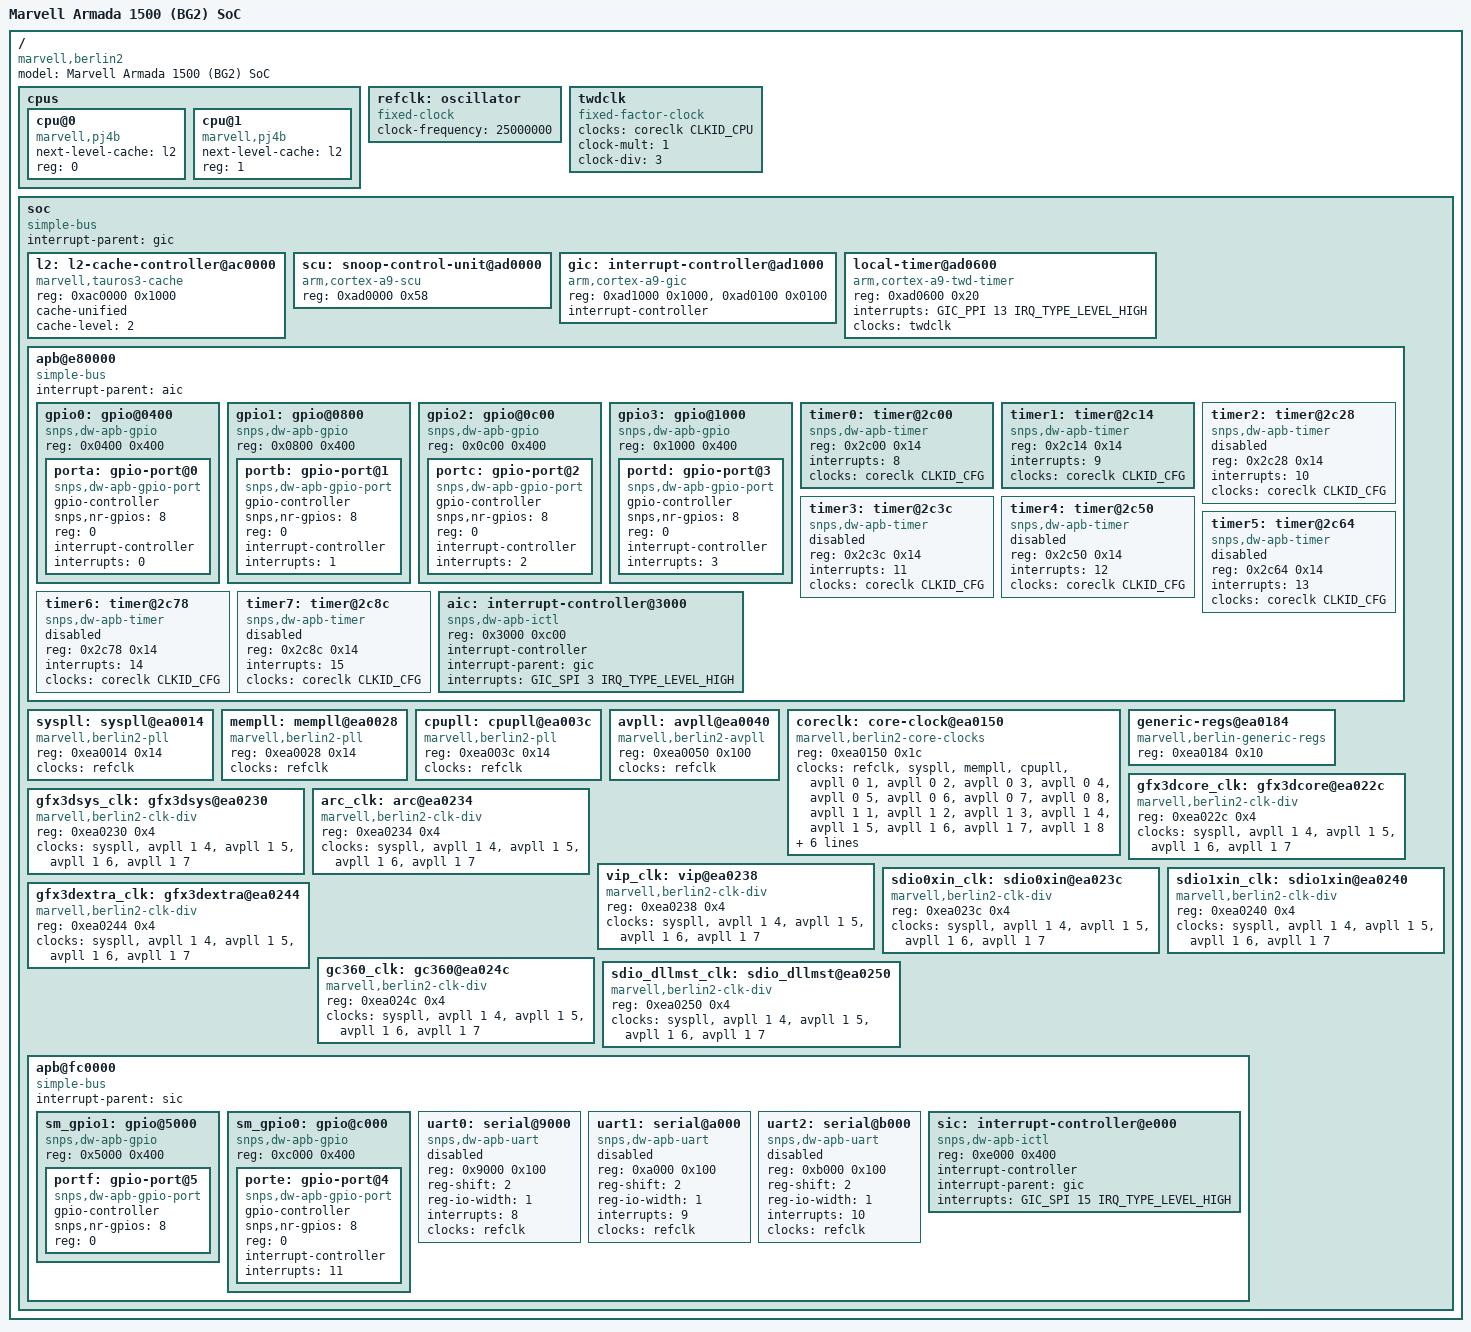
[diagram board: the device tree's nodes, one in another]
/*
 * Device Tree Include file for Marvell Armada 1500 (Berlin BG2) SoC
 *
 * Sebastian Hesselbarth <sebastian.hesselbarth@gmail.com>
 *
 * based on GPL'ed 2.6 kernel sources
 *  (c) Marvell International Ltd.
 *
 * This file is licensed under the terms of the GNU General Public
 * License version 2.  This program is licensed "as is" without any
 * warranty of any kind, whether express or implied.
 */

#include "skeleton.dtsi"
#include <dt-bindings/clock/berlin2.h>
#include <dt-bindings/interrupt-controller/arm-gic.h>

/ {
	model = "Marvell Armada 1500 (BG2) SoC";
	compatible = "marvell,berlin2", "marvell,berlin";

	cpus {
		#address-cells = <1>;
		#size-cells = <0>;

		cpu@0 {
			compatible = "marvell,pj4b";
			device_type = "cpu";
			next-level-cache = <&l2>;
			reg = <0>;
		};

		cpu@1 {
			compatible = "marvell,pj4b";
			device_type = "cpu";
			next-level-cache = <&l2>;
			reg = <1>;
		};
	};

	refclk: oscillator {
		compatible = "fixed-clock";
		#clock-cells = <0>;
		clock-frequency = <25000000>;
	};

	twdclk: twdclk {
		compatible = "fixed-factor-clock";
		#clock-cells = <0>;
		clocks = <&coreclk CLKID_CPU>;
		clock-mult = <1>;
		clock-div = <3>;
	};

	soc {
		compatible = "simple-bus";
		#address-cells = <1>;
		#size-cells = <1>;
		interrupt-parent = <&gic>;

		ranges = <0 0xf7000000 0x1000000>;

		l2: l2-cache-controller@ac0000 {
			compatible = "marvell,tauros3-cache", "arm,pl310-cache";
			reg = <0xac0000 0x1000>;
			cache-unified;
			cache-level = <2>;
		};

		scu: snoop-control-unit@ad0000 {
			compatible = "arm,cortex-a9-scu";
			reg = <0xad0000 0x58>;
		};

		gic: interrupt-controller@ad1000 {
			compatible = "arm,cortex-a9-gic";
			reg = <0xad1000 0x1000>, <0xad0100 0x0100>;
			interrupt-controller;
			#interrupt-cells = <3>;
		};

		local-timer@ad0600 {
			compatible = "arm,cortex-a9-twd-timer";
			reg = <0xad0600 0x20>;
			interrupts = <GIC_PPI 13 IRQ_TYPE_LEVEL_HIGH>;
			clocks = <&twdclk>;
		};

		apb@e80000 {
			compatible = "simple-bus";
			#address-cells = <1>;
			#size-cells = <1>;

			ranges = <0 0xe80000 0x10000>;
			interrupt-parent = <&aic>;

			gpio0: gpio@0400 {
				compatible = "snps,dw-apb-gpio";
				reg = <0x0400 0x400>;
				#address-cells = <1>;
				#size-cells = <0>;

				porta: gpio-port@0 {
					compatible = "snps,dw-apb-gpio-port";
					gpio-controller;
					#gpio-cells = <2>;
					snps,nr-gpios = <8>;
					reg = <0>;
					interrupt-controller;
					#interrupt-cells = <2>;
					interrupts = <0>;
				};
			};

			gpio1: gpio@0800 {
				compatible = "snps,dw-apb-gpio";
				reg = <0x0800 0x400>;
				#address-cells = <1>;
				#size-cells = <0>;

				portb: gpio-port@1 {
					compatible = "snps,dw-apb-gpio-port";
					gpio-controller;
					#gpio-cells = <2>;
					snps,nr-gpios = <8>;
					reg = <0>;
					interrupt-controller;
					#interrupt-cells = <2>;
					interrupts = <1>;
				};
			};

			gpio2: gpio@0c00 {
				compatible = "snps,dw-apb-gpio";
				reg = <0x0c00 0x400>;
				#address-cells = <1>;
				#size-cells = <0>;

				portc: gpio-port@2 {
					compatible = "snps,dw-apb-gpio-port";
					gpio-controller;
					#gpio-cells = <2>;
					snps,nr-gpios = <8>;
					reg = <0>;
					interrupt-controller;
					#interrupt-cells = <2>;
					interrupts = <2>;
				};
			};

			gpio3: gpio@1000 {
				compatible = "snps,dw-apb-gpio";
				reg = <0x1000 0x400>;
				#address-cells = <1>;
				#size-cells = <0>;

				portd: gpio-port@3 {
					compatible = "snps,dw-apb-gpio-port";
					gpio-controller;
					#gpio-cells = <2>;
					snps,nr-gpios = <8>;
					reg = <0>;
					interrupt-controller;
					#interrupt-cells = <2>;
					interrupts = <3>;
				};
			};

			timer0: timer@2c00 {
				compatible = "snps,dw-apb-timer";
				reg = <0x2c00 0x14>;
				interrupts = <8>;
				clocks = <&coreclk CLKID_CFG>;
				clock-names = "timer";
				status = "okay";
			};

			timer1: timer@2c14 {
				compatible = "snps,dw-apb-timer";
				reg = <0x2c14 0x14>;
				interrupts = <9>;
				clocks = <&coreclk CLKID_CFG>;
				clock-names = "timer";
				status = "okay";
			};

			timer2: timer@2c28 {
				compatible = "snps,dw-apb-timer";
				reg = <0x2c28 0x14>;
				interrupts = <10>;
				clocks = <&coreclk CLKID_CFG>;
				clock-names = "timer";
				status = "disabled";
			};

			timer3: timer@2c3c {
				compatible = "snps,dw-apb-timer";
				reg = <0x2c3c 0x14>;
				interrupts = <11>;
				clocks = <&coreclk CLKID_CFG>;
				clock-names = "timer";
				status = "disabled";
			};

			timer4: timer@2c50 {
				compatible = "snps,dw-apb-timer";
				reg = <0x2c50 0x14>;
				interrupts = <12>;
				clocks = <&coreclk CLKID_CFG>;
				clock-names = "timer";
				status = "disabled";
			};

			timer5: timer@2c64 {
				compatible = "snps,dw-apb-timer";
				reg = <0x2c64 0x14>;
				interrupts = <13>;
				clocks = <&coreclk CLKID_CFG>;
				clock-names = "timer";
				status = "disabled";
			};

			timer6: timer@2c78 {
				compatible = "snps,dw-apb-timer";
				reg = <0x2c78 0x14>;
				interrupts = <14>;
				clocks = <&coreclk CLKID_CFG>;
				clock-names = "timer";
				status = "disabled";
			};

			timer7: timer@2c8c {
				compatible = "snps,dw-apb-timer";
				reg = <0x2c8c 0x14>;
				interrupts = <15>;
				clocks = <&coreclk CLKID_CFG>;
				clock-names = "timer";
				status = "disabled";
			};

			aic: interrupt-controller@3000 {
				compatible = "snps,dw-apb-ictl";
				reg = <0x3000 0xc00>;
				interrupt-controller;
				#interrupt-cells = <1>;
				interrupt-parent = <&gic>;
				interrupts = <GIC_SPI 3 IRQ_TYPE_LEVEL_HIGH>;
			};
		};

		syspll: syspll@ea0014 {
			compatible = "marvell,berlin2-pll";
			#clock-cells = <0>;
			reg = <0xea0014 0x14>;
			clocks = <&refclk>;
		};

		mempll: mempll@ea0028 {
			compatible = "marvell,berlin2-pll";
			#clock-cells = <0>;
			reg = <0xea0028 0x14>;
			clocks = <&refclk>;
		};

		cpupll: cpupll@ea003c {
			compatible = "marvell,berlin2-pll";
			#clock-cells = <0>;
			reg = <0xea003c 0x14>;
			clocks = <&refclk>;
		};

		avpll: avpll@ea0040 {
			compatible = "marvell,berlin2-avpll";
			#clock-cells = <2>;
			reg = <0xea0050 0x100>;
			clocks = <&refclk>;
		};

		coreclk: core-clock@ea0150 {
			compatible = "marvell,berlin2-core-clocks";
			#clock-cells = <1>;
			reg = <0xea0150 0x1c>;
			clocks = <&refclk>, <&syspll>, <&mempll>, <&cpupll>,
				<&avpll 0 1>, <&avpll 0 2>,
				<&avpll 0 3>, <&avpll 0 4>,
				<&avpll 0 5>, <&avpll 0 6>,
				<&avpll 0 7>, <&avpll 0 8>,
				<&avpll 1 1>, <&avpll 1 2>,
				<&avpll 1 3>, <&avpll 1 4>,
				<&avpll 1 5>, <&avpll 1 6>,
				<&avpll 1 7>, <&avpll 1 8>;
			clock-names = "refclk", "syspll", "mempll", "cpupll",
				"avpll_a1", "avpll_a2", "avpll_a3", "avpll_a4",
				"avpll_a5", "avpll_a6", "avpll_a7", "avpll_a8",
				"avpll_b1", "avpll_b2", "avpll_b3", "avpll_b4",
				"avpll_b5", "avpll_b6", "avpll_b7", "avpll_b8";
			clock-output-names = "sys", "cpu", "drmfigo", "cfg",
				"gfx", "zsp", "perif", "pcube", "vscope",
				"nfc_ecc", "vpp", "app", "audio0", "audio2",
				"audio3", "audio1", "geth0", "geth1", "sata",
				"ahbapb", "usb0", "usb1", "pbridge", "sdio0",
				"sdio1", "nfc", "smemc", "audiohd", "video0",
				"video1", "video2";
		};

		generic-regs@ea0184 {
			compatible = "marvell,berlin-generic-regs", "syscon";
			reg = <0xea0184 0x10>;
		};

		gfx3dcore_clk: gfx3dcore@ea022c {
			compatible = "marvell,berlin2-clk-div";
			#clock-cells = <0>;
			reg = <0xea022c 0x4>;
			clocks = <&syspll>,
				<&avpll 1 4>, <&avpll 1 5>,
				<&avpll 1 6>, <&avpll 1 7>;
			clock-names = "mux_bypass",
				"mux0", "mux1", "mux2", "mux3";
		};

		gfx3dsys_clk: gfx3dsys@ea0230 {
			compatible = "marvell,berlin2-clk-div";
			#clock-cells = <0>;
			reg = <0xea0230 0x4>;
			clocks = <&syspll>,
				<&avpll 1 4>, <&avpll 1 5>,
				<&avpll 1 6>, <&avpll 1 7>;
			clock-names = "mux_bypass",
				"mux0", "mux1", "mux2", "mux3";
		};

		arc_clk: arc@ea0234 {
			compatible = "marvell,berlin2-clk-div";
			#clock-cells = <0>;
			reg = <0xea0234 0x4>;
			clocks = <&syspll>,
				<&avpll 1 4>, <&avpll 1 5>,
				<&avpll 1 6>, <&avpll 1 7>;
			clock-names = "mux_bypass",
				"mux0", "mux1", "mux2", "mux3";
		};

		vip_clk: vip@ea0238 {
			compatible = "marvell,berlin2-clk-div";
			#clock-cells = <0>;
			reg = <0xea0238 0x4>;
			clocks = <&syspll>,
				<&avpll 1 4>, <&avpll 1 5>,
				<&avpll 1 6>, <&avpll 1 7>;
			clock-names = "mux_bypass",
				"mux0", "mux1", "mux2", "mux3";
		};

		sdio0xin_clk: sdio0xin@ea023c {
			compatible = "marvell,berlin2-clk-div";
			#clock-cells = <0>;
			reg = <0xea023c 0x4>;
			clocks = <&syspll>,
				<&avpll 1 4>, <&avpll 1 5>,
				<&avpll 1 6>, <&avpll 1 7>;
			clock-names = "mux_bypass",
				"mux0", "mux1", "mux2", "mux3";
		};

		sdio1xin_clk: sdio1xin@ea0240 {
			compatible = "marvell,berlin2-clk-div";
			#clock-cells = <0>;
			reg = <0xea0240 0x4>;
			clocks = <&syspll>,
				<&avpll 1 4>, <&avpll 1 5>,
				<&avpll 1 6>, <&avpll 1 7>;
			clock-names = "mux_bypass",
				"mux0", "mux1", "mux2", "mux3";
		};

		gfx3dextra_clk: gfx3dextra@ea0244 {
			compatible = "marvell,berlin2-clk-div";
			#clock-cells = <0>;
			reg = <0xea0244 0x4>;
			clocks = <&syspll>,
				<&avpll 1 4>, <&avpll 1 5>,
				<&avpll 1 6>, <&avpll 1 7>;
			clock-names = "mux_bypass",
				"mux0", "mux1", "mux2", "mux3";
		};

		gc360_clk: gc360@ea024c {
			compatible = "marvell,berlin2-clk-div";
			#clock-cells = <0>;
			reg = <0xea024c 0x4>;
			clocks = <&syspll>,
				<&avpll 1 4>, <&avpll 1 5>,
				<&avpll 1 6>, <&avpll 1 7>;
			clock-names = "mux_bypass",
				"mux0", "mux1", "mux2", "mux3";
		};

		sdio_dllmst_clk: sdio_dllmst@ea0250 {
			compatible = "marvell,berlin2-clk-div";
			#clock-cells = <0>;
			reg = <0xea0250 0x4>;
			clocks = <&syspll>,
				<&avpll 1 4>, <&avpll 1 5>,
				<&avpll 1 6>, <&avpll 1 7>;
			clock-names = "mux_bypass",
				"mux0", "mux1", "mux2", "mux3";
		};

		apb@fc0000 {
			compatible = "simple-bus";
			#address-cells = <1>;
			#size-cells = <1>;

			ranges = <0 0xfc0000 0x10000>;
			interrupt-parent = <&sic>;

			sm_gpio1: gpio@5000 {
				compatible = "snps,dw-apb-gpio";
				reg = <0x5000 0x400>;
				#address-cells = <1>;
				#size-cells = <0>;

				portf: gpio-port@5 {
					compatible = "snps,dw-apb-gpio-port";
					gpio-controller;
					#gpio-cells = <2>;
					snps,nr-gpios = <8>;
					reg = <0>;
				};
			};

			sm_gpio0: gpio@c000 {
				compatible = "snps,dw-apb-gpio";
				reg = <0xc000 0x400>;
				#address-cells = <1>;
				#size-cells = <0>;

				porte: gpio-port@4 {
					compatible = "snps,dw-apb-gpio-port";
					gpio-controller;
					#gpio-cells = <2>;
					snps,nr-gpios = <8>;
					reg = <0>;
					interrupt-controller;
					#interrupt-cells = <2>;
					interrupts = <11>;
				};
			};

			uart0: serial@9000 {
				compatible = "snps,dw-apb-uart";
				reg = <0x9000 0x100>;
				reg-shift = <2>;
				reg-io-width = <1>;
				interrupts = <8>;
				clocks = <&refclk>;
				status = "disabled";
			};

			uart1: serial@a000 {
				compatible = "snps,dw-apb-uart";
				reg = <0xa000 0x100>;
				reg-shift = <2>;
				reg-io-width = <1>;
				interrupts = <9>;
				clocks = <&refclk>;
				status = "disabled";
			};

			uart2: serial@b000 {
				compatible = "snps,dw-apb-uart";
				reg = <0xb000 0x100>;
				reg-shift = <2>;
				reg-io-width = <1>;
				interrupts = <10>;
				clocks = <&refclk>;
				status = "disabled";
			};

			sic: interrupt-controller@e000 {
				compatible = "snps,dw-apb-ictl";
				reg = <0xe000 0x400>;
				interrupt-controller;
				#interrupt-cells = <1>;
				interrupt-parent = <&gic>;
				interrupts = <GIC_SPI 15 IRQ_TYPE_LEVEL_HIGH>;
			};
		};
	};
};
